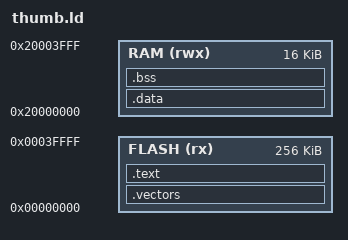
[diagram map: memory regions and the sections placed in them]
/* The memory both Cortex-M machines have: flash at 0 (the micro:bit's 256 KiB), RAM at 0x2000_0000
 * (the micro:bit's 16 KiB). */
ENTRY(_start)
MEMORY {
  FLASH (rx) : ORIGIN = 0x00000000, LENGTH = 256K
  RAM (rwx)  : ORIGIN = 0x20000000, LENGTH = 16K
}
SECTIONS {
  .vectors : { KEEP(*(.vectors)) } > FLASH
  .text : { *(.text*) *(.rodata*) } > FLASH
  .data : { *(.data*) } > RAM
  .bss : { *(.bss*) *(COMMON) } > RAM
  _stack_top = ORIGIN(RAM) + LENGTH(RAM);
}
